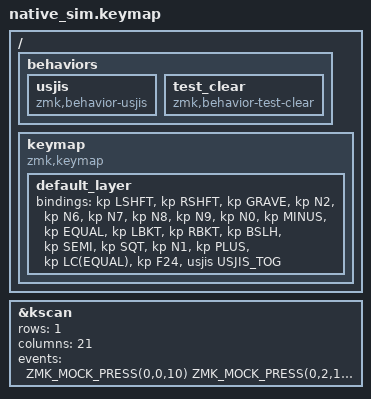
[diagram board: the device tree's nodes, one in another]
/* Generated by tests/zmk/generate.py; do not edit. */
#include <dt-bindings/zmk/keys.h>
#include <behaviors.dtsi>
#include <dt-bindings/zmk/kscan_mock.h>
#include <dt-bindings/zmk/usjis.h>

&kscan {
    rows = <1>;
    columns = <21>;
    events = <
        ZMK_MOCK_PRESS(0,0,10)
        ZMK_MOCK_PRESS(0,2,10)
        ZMK_MOCK_RELEASE(0,2,10)
        ZMK_MOCK_RELEASE(0,0,10)
        ZMK_MOCK_PRESS(0,0,10)
        ZMK_MOCK_PRESS(0,2,10)
        ZMK_MOCK_RELEASE(0,0,10)
        ZMK_MOCK_RELEASE(0,2,10)
        ZMK_MOCK_PRESS(0,1,10)
        ZMK_MOCK_PRESS(0,2,10)
        ZMK_MOCK_RELEASE(0,2,10)
        ZMK_MOCK_RELEASE(0,1,10)
        ZMK_MOCK_PRESS(0,1,10)
        ZMK_MOCK_PRESS(0,2,10)
        ZMK_MOCK_RELEASE(0,1,10)
        ZMK_MOCK_RELEASE(0,2,10)
        ZMK_MOCK_PRESS(0,0,10)
        ZMK_MOCK_PRESS(0,1,10)
        ZMK_MOCK_PRESS(0,2,10)
        ZMK_MOCK_RELEASE(0,2,10)
        ZMK_MOCK_RELEASE(0,1,10)
        ZMK_MOCK_RELEASE(0,0,10)
        ZMK_MOCK_PRESS(0,0,10)
        ZMK_MOCK_PRESS(0,1,10)
        ZMK_MOCK_PRESS(0,2,10)
        ZMK_MOCK_RELEASE(0,1,10)
        ZMK_MOCK_RELEASE(0,0,10)
        ZMK_MOCK_RELEASE(0,2,10)
        ZMK_MOCK_PRESS(0,19,10)
        ZMK_MOCK_RELEASE(0,19,10)
        ZMK_MOCK_PRESS(0,0,10)
        ZMK_MOCK_PRESS(0,3,10)
        ZMK_MOCK_RELEASE(0,3,10)
        ZMK_MOCK_RELEASE(0,0,10)
        ZMK_MOCK_PRESS(0,0,10)
        ZMK_MOCK_PRESS(0,3,10)
        ZMK_MOCK_RELEASE(0,0,10)
        ZMK_MOCK_RELEASE(0,3,10)
        ZMK_MOCK_PRESS(0,1,10)
        ZMK_MOCK_PRESS(0,3,10)
        ZMK_MOCK_RELEASE(0,3,10)
        ZMK_MOCK_RELEASE(0,1,10)
        ZMK_MOCK_PRESS(0,1,10)
        ZMK_MOCK_PRESS(0,3,10)
        ZMK_MOCK_RELEASE(0,1,10)
        ZMK_MOCK_RELEASE(0,3,10)
        ZMK_MOCK_PRESS(0,0,10)
        ZMK_MOCK_PRESS(0,1,10)
        ZMK_MOCK_PRESS(0,3,10)
        ZMK_MOCK_RELEASE(0,3,10)
        ZMK_MOCK_RELEASE(0,1,10)
        ZMK_MOCK_RELEASE(0,0,10)
        ZMK_MOCK_PRESS(0,0,10)
        ZMK_MOCK_PRESS(0,1,10)
        ZMK_MOCK_PRESS(0,3,10)
        ZMK_MOCK_RELEASE(0,1,10)
        ZMK_MOCK_RELEASE(0,0,10)
        ZMK_MOCK_RELEASE(0,3,10)
        ZMK_MOCK_PRESS(0,19,10)
        ZMK_MOCK_RELEASE(0,19,10)
        ZMK_MOCK_PRESS(0,0,10)
        ZMK_MOCK_PRESS(0,4,10)
        ZMK_MOCK_RELEASE(0,4,10)
        ZMK_MOCK_RELEASE(0,0,10)
        ZMK_MOCK_PRESS(0,0,10)
        ZMK_MOCK_PRESS(0,4,10)
        ZMK_MOCK_RELEASE(0,0,10)
        ZMK_MOCK_RELEASE(0,4,10)
        ZMK_MOCK_PRESS(0,1,10)
        ZMK_MOCK_PRESS(0,4,10)
        ZMK_MOCK_RELEASE(0,4,10)
        ZMK_MOCK_RELEASE(0,1,10)
        ZMK_MOCK_PRESS(0,1,10)
        ZMK_MOCK_PRESS(0,4,10)
        ZMK_MOCK_RELEASE(0,1,10)
        ZMK_MOCK_RELEASE(0,4,10)
        ZMK_MOCK_PRESS(0,0,10)
        ZMK_MOCK_PRESS(0,1,10)
        ZMK_MOCK_PRESS(0,4,10)
        ZMK_MOCK_RELEASE(0,4,10)
        ZMK_MOCK_RELEASE(0,1,10)
        ZMK_MOCK_RELEASE(0,0,10)
        ZMK_MOCK_PRESS(0,0,10)
        ZMK_MOCK_PRESS(0,1,10)
        ZMK_MOCK_PRESS(0,4,10)
        ZMK_MOCK_RELEASE(0,1,10)
        ZMK_MOCK_RELEASE(0,0,10)
        ZMK_MOCK_RELEASE(0,4,10)
        ZMK_MOCK_PRESS(0,19,10)
        ZMK_MOCK_RELEASE(0,19,10)
        ZMK_MOCK_PRESS(0,0,10)
        ZMK_MOCK_PRESS(0,5,10)
        ZMK_MOCK_RELEASE(0,5,10)
        ZMK_MOCK_RELEASE(0,0,10)
        ZMK_MOCK_PRESS(0,0,10)
        ZMK_MOCK_PRESS(0,5,10)
        ZMK_MOCK_RELEASE(0,0,10)
        ZMK_MOCK_RELEASE(0,5,10)
        ZMK_MOCK_PRESS(0,1,10)
        ZMK_MOCK_PRESS(0,5,10)
        ZMK_MOCK_RELEASE(0,5,10)
        ZMK_MOCK_RELEASE(0,1,10)
        ZMK_MOCK_PRESS(0,1,10)
        ZMK_MOCK_PRESS(0,5,10)
        ZMK_MOCK_RELEASE(0,1,10)
        ZMK_MOCK_RELEASE(0,5,10)
        ZMK_MOCK_PRESS(0,0,10)
        ZMK_MOCK_PRESS(0,1,10)
        ZMK_MOCK_PRESS(0,5,10)
        ZMK_MOCK_RELEASE(0,5,10)
        ZMK_MOCK_RELEASE(0,1,10)
        ZMK_MOCK_RELEASE(0,0,10)
        ZMK_MOCK_PRESS(0,0,10)
        ZMK_MOCK_PRESS(0,1,10)
        ZMK_MOCK_PRESS(0,5,10)
        ZMK_MOCK_RELEASE(0,1,10)
        ZMK_MOCK_RELEASE(0,0,10)
        ZMK_MOCK_RELEASE(0,5,10)
        ZMK_MOCK_PRESS(0,19,10)
        ZMK_MOCK_RELEASE(0,19,10)
        ZMK_MOCK_PRESS(0,0,10)
        ZMK_MOCK_PRESS(0,6,10)
        ZMK_MOCK_RELEASE(0,6,10)
        ZMK_MOCK_RELEASE(0,0,10)
        ZMK_MOCK_PRESS(0,0,10)
        ZMK_MOCK_PRESS(0,6,10)
        ZMK_MOCK_RELEASE(0,0,10)
        ZMK_MOCK_RELEASE(0,6,10)
        ZMK_MOCK_PRESS(0,1,10)
        ZMK_MOCK_PRESS(0,6,10)
        ZMK_MOCK_RELEASE(0,6,10)
        ZMK_MOCK_RELEASE(0,1,10)
        ZMK_MOCK_PRESS(0,1,10)
        ZMK_MOCK_PRESS(0,6,10)
        ZMK_MOCK_RELEASE(0,1,10)
        ZMK_MOCK_RELEASE(0,6,10)
        ZMK_MOCK_PRESS(0,0,10)
        ZMK_MOCK_PRESS(0,1,10)
        ZMK_MOCK_PRESS(0,6,10)
        ZMK_MOCK_RELEASE(0,6,10)
        ZMK_MOCK_RELEASE(0,1,10)
        ZMK_MOCK_RELEASE(0,0,10)
        ZMK_MOCK_PRESS(0,0,10)
        ZMK_MOCK_PRESS(0,1,10)
        ZMK_MOCK_PRESS(0,6,10)
        ZMK_MOCK_RELEASE(0,1,10)
        ZMK_MOCK_RELEASE(0,0,10)
        ZMK_MOCK_RELEASE(0,6,10)
        ZMK_MOCK_PRESS(0,19,10)
        ZMK_MOCK_RELEASE(0,19,10)
        ZMK_MOCK_PRESS(0,0,10)
        ZMK_MOCK_PRESS(0,7,10)
        ZMK_MOCK_RELEASE(0,7,10)
        ZMK_MOCK_RELEASE(0,0,10)
        ZMK_MOCK_PRESS(0,0,10)
        ZMK_MOCK_PRESS(0,7,10)
        ZMK_MOCK_RELEASE(0,0,10)
        ZMK_MOCK_RELEASE(0,7,10)
        ZMK_MOCK_PRESS(0,1,10)
        ZMK_MOCK_PRESS(0,7,10)
        ZMK_MOCK_RELEASE(0,7,10)
        ZMK_MOCK_RELEASE(0,1,10)
        ZMK_MOCK_PRESS(0,1,10)
        ZMK_MOCK_PRESS(0,7,10)
        ZMK_MOCK_RELEASE(0,1,10)
        ZMK_MOCK_RELEASE(0,7,10)
        ZMK_MOCK_PRESS(0,0,10)
        ZMK_MOCK_PRESS(0,1,10)
        ZMK_MOCK_PRESS(0,7,10)
        ZMK_MOCK_RELEASE(0,7,10)
        ZMK_MOCK_RELEASE(0,1,10)
        ZMK_MOCK_RELEASE(0,0,10)
        ZMK_MOCK_PRESS(0,0,10)
        ZMK_MOCK_PRESS(0,1,10)
        ZMK_MOCK_PRESS(0,7,10)
        ZMK_MOCK_RELEASE(0,1,10)
        ZMK_MOCK_RELEASE(0,0,10)
        ZMK_MOCK_RELEASE(0,7,10)
        ZMK_MOCK_PRESS(0,19,10)
        ZMK_MOCK_RELEASE(0,19,10)
        ZMK_MOCK_PRESS(0,0,10)
        ZMK_MOCK_PRESS(0,8,10)
        ZMK_MOCK_RELEASE(0,8,10)
        ZMK_MOCK_RELEASE(0,0,10)
        ZMK_MOCK_PRESS(0,0,10)
        ZMK_MOCK_PRESS(0,8,10)
        ZMK_MOCK_RELEASE(0,0,10)
        ZMK_MOCK_RELEASE(0,8,10)
        ZMK_MOCK_PRESS(0,1,10)
        ZMK_MOCK_PRESS(0,8,10)
        ZMK_MOCK_RELEASE(0,8,10)
        ZMK_MOCK_RELEASE(0,1,10)
        ZMK_MOCK_PRESS(0,1,10)
        ZMK_MOCK_PRESS(0,8,10)
        ZMK_MOCK_RELEASE(0,1,10)
        ZMK_MOCK_RELEASE(0,8,10)
        ZMK_MOCK_PRESS(0,0,10)
        ZMK_MOCK_PRESS(0,1,10)
        ZMK_MOCK_PRESS(0,8,10)
        ZMK_MOCK_RELEASE(0,8,10)
        ZMK_MOCK_RELEASE(0,1,10)
        ZMK_MOCK_RELEASE(0,0,10)
        ZMK_MOCK_PRESS(0,0,10)
        ZMK_MOCK_PRESS(0,1,10)
        ZMK_MOCK_PRESS(0,8,10)
        ZMK_MOCK_RELEASE(0,1,10)
        ZMK_MOCK_RELEASE(0,0,10)
        ZMK_MOCK_RELEASE(0,8,10)
        ZMK_MOCK_PRESS(0,19,10)
        ZMK_MOCK_RELEASE(0,19,10)
        ZMK_MOCK_PRESS(0,0,10)
        ZMK_MOCK_PRESS(0,9,10)
        ZMK_MOCK_RELEASE(0,9,10)
        ZMK_MOCK_RELEASE(0,0,10)
        ZMK_MOCK_PRESS(0,0,10)
        ZMK_MOCK_PRESS(0,9,10)
        ZMK_MOCK_RELEASE(0,0,10)
        ZMK_MOCK_RELEASE(0,9,10)
        ZMK_MOCK_PRESS(0,1,10)
        ZMK_MOCK_PRESS(0,9,10)
        ZMK_MOCK_RELEASE(0,9,10)
        ZMK_MOCK_RELEASE(0,1,10)
        ZMK_MOCK_PRESS(0,1,10)
        ZMK_MOCK_PRESS(0,9,10)
        ZMK_MOCK_RELEASE(0,1,10)
        ZMK_MOCK_RELEASE(0,9,10)
        ZMK_MOCK_PRESS(0,0,10)
        ZMK_MOCK_PRESS(0,1,10)
        ZMK_MOCK_PRESS(0,9,10)
        ZMK_MOCK_RELEASE(0,9,10)
        ZMK_MOCK_RELEASE(0,1,10)
        ZMK_MOCK_RELEASE(0,0,10)
        ZMK_MOCK_PRESS(0,0,10)
        ZMK_MOCK_PRESS(0,1,10)
        ZMK_MOCK_PRESS(0,9,10)
        ZMK_MOCK_RELEASE(0,1,10)
        ZMK_MOCK_RELEASE(0,0,10)
        ZMK_MOCK_RELEASE(0,9,10)
        ZMK_MOCK_PRESS(0,19,10)
        ZMK_MOCK_RELEASE(0,19,10)
        ZMK_MOCK_PRESS(0,10,10)
        ZMK_MOCK_RELEASE(0,10,10)
        ZMK_MOCK_PRESS(0,19,10)
        ZMK_MOCK_RELEASE(0,19,10)
        ZMK_MOCK_PRESS(0,0,10)
        ZMK_MOCK_PRESS(0,10,10)
        ZMK_MOCK_RELEASE(0,10,10)
        ZMK_MOCK_RELEASE(0,0,10)
        ZMK_MOCK_PRESS(0,0,10)
        ZMK_MOCK_PRESS(0,10,10)
        ZMK_MOCK_RELEASE(0,0,10)
        ZMK_MOCK_RELEASE(0,10,10)
        ZMK_MOCK_PRESS(0,1,10)
        ZMK_MOCK_PRESS(0,10,10)
        ZMK_MOCK_RELEASE(0,10,10)
        ZMK_MOCK_RELEASE(0,1,10)
        ZMK_MOCK_PRESS(0,1,10)
        ZMK_MOCK_PRESS(0,10,10)
        ZMK_MOCK_RELEASE(0,1,10)
        ZMK_MOCK_RELEASE(0,10,10)
        ZMK_MOCK_PRESS(0,0,10)
        ZMK_MOCK_PRESS(0,1,10)
        ZMK_MOCK_PRESS(0,10,10)
        ZMK_MOCK_RELEASE(0,10,10)
        ZMK_MOCK_RELEASE(0,1,10)
        ZMK_MOCK_RELEASE(0,0,10)
        ZMK_MOCK_PRESS(0,0,10)
        ZMK_MOCK_PRESS(0,1,10)
        ZMK_MOCK_PRESS(0,10,10)
        ZMK_MOCK_RELEASE(0,1,10)
        ZMK_MOCK_RELEASE(0,0,10)
        ZMK_MOCK_RELEASE(0,10,10)
        ZMK_MOCK_PRESS(0,19,10)
        ZMK_MOCK_RELEASE(0,19,10)
        ZMK_MOCK_PRESS(0,11,10)
        ZMK_MOCK_RELEASE(0,11,10)
        ZMK_MOCK_PRESS(0,19,10)
        ZMK_MOCK_RELEASE(0,19,10)
        ZMK_MOCK_PRESS(0,0,10)
        ZMK_MOCK_PRESS(0,11,10)
        ZMK_MOCK_RELEASE(0,11,10)
        ZMK_MOCK_RELEASE(0,0,10)
        ZMK_MOCK_PRESS(0,0,10)
        ZMK_MOCK_PRESS(0,11,10)
        ZMK_MOCK_RELEASE(0,0,10)
        ZMK_MOCK_RELEASE(0,11,10)
        ZMK_MOCK_PRESS(0,1,10)
        ZMK_MOCK_PRESS(0,11,10)
        ZMK_MOCK_RELEASE(0,11,10)
        ZMK_MOCK_RELEASE(0,1,10)
        ZMK_MOCK_PRESS(0,1,10)
        ZMK_MOCK_PRESS(0,11,10)
        ZMK_MOCK_RELEASE(0,1,10)
        ZMK_MOCK_RELEASE(0,11,10)
        ZMK_MOCK_PRESS(0,0,10)
        ZMK_MOCK_PRESS(0,1,10)
        ZMK_MOCK_PRESS(0,11,10)
        ZMK_MOCK_RELEASE(0,11,10)
        ZMK_MOCK_RELEASE(0,1,10)
        ZMK_MOCK_RELEASE(0,0,10)
        ZMK_MOCK_PRESS(0,0,10)
        ZMK_MOCK_PRESS(0,1,10)
        ZMK_MOCK_PRESS(0,11,10)
        ZMK_MOCK_RELEASE(0,1,10)
        ZMK_MOCK_RELEASE(0,0,10)
        ZMK_MOCK_RELEASE(0,11,10)
        ZMK_MOCK_PRESS(0,19,10)
        ZMK_MOCK_RELEASE(0,19,10)
        ZMK_MOCK_PRESS(0,12,10)
        ZMK_MOCK_RELEASE(0,12,10)
        ZMK_MOCK_PRESS(0,19,10)
        ZMK_MOCK_RELEASE(0,19,10)
        ZMK_MOCK_PRESS(0,0,10)
        ZMK_MOCK_PRESS(0,12,10)
        ZMK_MOCK_RELEASE(0,12,10)
        ZMK_MOCK_RELEASE(0,0,10)
        ZMK_MOCK_PRESS(0,0,10)
        ZMK_MOCK_PRESS(0,12,10)
        ZMK_MOCK_RELEASE(0,0,10)
        ZMK_MOCK_RELEASE(0,12,10)
        ZMK_MOCK_PRESS(0,1,10)
        ZMK_MOCK_PRESS(0,12,10)
        ZMK_MOCK_RELEASE(0,12,10)
        ZMK_MOCK_RELEASE(0,1,10)
        ZMK_MOCK_PRESS(0,1,10)
        ZMK_MOCK_PRESS(0,12,10)
        ZMK_MOCK_RELEASE(0,1,10)
        ZMK_MOCK_RELEASE(0,12,10)
        ZMK_MOCK_PRESS(0,0,10)
        ZMK_MOCK_PRESS(0,1,10)
        ZMK_MOCK_PRESS(0,12,10)
        ZMK_MOCK_RELEASE(0,12,10)
        ZMK_MOCK_RELEASE(0,1,10)
        ZMK_MOCK_RELEASE(0,0,10)
        ZMK_MOCK_PRESS(0,0,10)
        ZMK_MOCK_PRESS(0,1,10)
        ZMK_MOCK_PRESS(0,12,10)
        ZMK_MOCK_RELEASE(0,1,10)
        ZMK_MOCK_RELEASE(0,0,10)
        ZMK_MOCK_RELEASE(0,12,10)
        ZMK_MOCK_PRESS(0,19,10)
        ZMK_MOCK_RELEASE(0,19,10)
        ZMK_MOCK_PRESS(0,13,10)
        ZMK_MOCK_RELEASE(0,13,10)
        ZMK_MOCK_PRESS(0,19,10)
        ZMK_MOCK_RELEASE(0,19,10)
        ZMK_MOCK_PRESS(0,0,10)
        ZMK_MOCK_PRESS(0,13,10)
        ZMK_MOCK_RELEASE(0,13,10)
        ZMK_MOCK_RELEASE(0,0,10)
        ZMK_MOCK_PRESS(0,0,10)
        ZMK_MOCK_PRESS(0,13,10)
        ZMK_MOCK_RELEASE(0,0,10)
        ZMK_MOCK_RELEASE(0,13,10)
        ZMK_MOCK_PRESS(0,1,10)
        ZMK_MOCK_PRESS(0,13,10)
        ZMK_MOCK_RELEASE(0,13,10)
        ZMK_MOCK_RELEASE(0,1,10)
        ZMK_MOCK_PRESS(0,1,10)
        ZMK_MOCK_PRESS(0,13,10)
        ZMK_MOCK_RELEASE(0,1,10)
        ZMK_MOCK_RELEASE(0,13,10)
        ZMK_MOCK_PRESS(0,0,10)
        ZMK_MOCK_PRESS(0,1,10)
        ZMK_MOCK_PRESS(0,13,10)
        ZMK_MOCK_RELEASE(0,13,10)
        ZMK_MOCK_RELEASE(0,1,10)
        ZMK_MOCK_RELEASE(0,0,10)
        ZMK_MOCK_PRESS(0,0,10)
        ZMK_MOCK_PRESS(0,1,10)
        ZMK_MOCK_PRESS(0,13,10)
        ZMK_MOCK_RELEASE(0,1,10)
        ZMK_MOCK_RELEASE(0,0,10)
        ZMK_MOCK_RELEASE(0,13,10)
        ZMK_MOCK_PRESS(0,19,10)
        ZMK_MOCK_RELEASE(0,19,10)
        ZMK_MOCK_PRESS(0,0,10)
        ZMK_MOCK_PRESS(0,14,10)
        ZMK_MOCK_RELEASE(0,14,10)
        ZMK_MOCK_RELEASE(0,0,10)
        ZMK_MOCK_PRESS(0,0,10)
        ZMK_MOCK_PRESS(0,14,10)
        ZMK_MOCK_RELEASE(0,0,10)
        ZMK_MOCK_RELEASE(0,14,10)
        ZMK_MOCK_PRESS(0,1,10)
        ZMK_MOCK_PRESS(0,14,10)
        ZMK_MOCK_RELEASE(0,14,10)
        ZMK_MOCK_RELEASE(0,1,10)
        ZMK_MOCK_PRESS(0,1,10)
        ZMK_MOCK_PRESS(0,14,10)
        ZMK_MOCK_RELEASE(0,1,10)
        ZMK_MOCK_RELEASE(0,14,10)
        ZMK_MOCK_PRESS(0,0,10)
        ZMK_MOCK_PRESS(0,1,10)
        ZMK_MOCK_PRESS(0,14,10)
        ZMK_MOCK_RELEASE(0,14,10)
        ZMK_MOCK_RELEASE(0,1,10)
        ZMK_MOCK_RELEASE(0,0,10)
        ZMK_MOCK_PRESS(0,0,10)
        ZMK_MOCK_PRESS(0,1,10)
        ZMK_MOCK_PRESS(0,14,10)
        ZMK_MOCK_RELEASE(0,1,10)
        ZMK_MOCK_RELEASE(0,0,10)
        ZMK_MOCK_RELEASE(0,14,10)
        ZMK_MOCK_PRESS(0,19,10)
        ZMK_MOCK_RELEASE(0,19,10)
        ZMK_MOCK_PRESS(0,15,10)
        ZMK_MOCK_RELEASE(0,15,10)
        ZMK_MOCK_PRESS(0,19,10)
        ZMK_MOCK_RELEASE(0,19,10)
        ZMK_MOCK_PRESS(0,0,10)
        ZMK_MOCK_PRESS(0,15,10)
        ZMK_MOCK_RELEASE(0,15,10)
        ZMK_MOCK_RELEASE(0,0,10)
        ZMK_MOCK_PRESS(0,0,10)
        ZMK_MOCK_PRESS(0,15,10)
        ZMK_MOCK_RELEASE(0,0,10)
        ZMK_MOCK_RELEASE(0,15,10)
        ZMK_MOCK_PRESS(0,1,10)
        ZMK_MOCK_PRESS(0,15,10)
        ZMK_MOCK_RELEASE(0,15,10)
        ZMK_MOCK_RELEASE(0,1,10)
        ZMK_MOCK_PRESS(0,1,10)
        ZMK_MOCK_PRESS(0,15,10)
        ZMK_MOCK_RELEASE(0,1,10)
        ZMK_MOCK_RELEASE(0,15,10)
        ZMK_MOCK_PRESS(0,0,10)
        ZMK_MOCK_PRESS(0,1,10)
        ZMK_MOCK_PRESS(0,15,10)
        ZMK_MOCK_RELEASE(0,15,10)
        ZMK_MOCK_RELEASE(0,1,10)
        ZMK_MOCK_RELEASE(0,0,10)
        ZMK_MOCK_PRESS(0,0,10)
        ZMK_MOCK_PRESS(0,1,10)
        ZMK_MOCK_PRESS(0,15,10)
        ZMK_MOCK_RELEASE(0,1,10)
        ZMK_MOCK_RELEASE(0,0,10)
        ZMK_MOCK_RELEASE(0,15,10)
        ZMK_MOCK_PRESS(0,19,10)
        ZMK_MOCK_RELEASE(0,19,10)
        ZMK_MOCK_PRESS(0,2,10)
        ZMK_MOCK_RELEASE(0,2,10)
        ZMK_MOCK_PRESS(0,19,10)
        ZMK_MOCK_RELEASE(0,19,10)
        ZMK_MOCK_PRESS(0,3,10)
        ZMK_MOCK_RELEASE(0,3,10)
        ZMK_MOCK_PRESS(0,4,10)
        ZMK_MOCK_RELEASE(0,4,10)
        ZMK_MOCK_PRESS(0,5,10)
        ZMK_MOCK_RELEASE(0,5,10)
        ZMK_MOCK_PRESS(0,6,10)
        ZMK_MOCK_RELEASE(0,6,10)
        ZMK_MOCK_PRESS(0,7,10)
        ZMK_MOCK_RELEASE(0,7,10)
        ZMK_MOCK_PRESS(0,8,10)
        ZMK_MOCK_RELEASE(0,8,10)
        ZMK_MOCK_PRESS(0,9,10)
        ZMK_MOCK_RELEASE(0,9,10)
        ZMK_MOCK_PRESS(0,14,10)
        ZMK_MOCK_RELEASE(0,14,10)
        ZMK_MOCK_PRESS(0,1,10)
        ZMK_MOCK_PRESS(0,16,10)
        ZMK_MOCK_RELEASE(0,16,10)
        ZMK_MOCK_RELEASE(0,1,10)
        ZMK_MOCK_PRESS(0,19,10)
        ZMK_MOCK_RELEASE(0,19,10)
        ZMK_MOCK_PRESS(0,17,10)
        ZMK_MOCK_RELEASE(0,17,10)
        ZMK_MOCK_PRESS(0,18,10)
        ZMK_MOCK_RELEASE(0,18,10)
        ZMK_MOCK_PRESS(0,19,10)
        ZMK_MOCK_RELEASE(0,19,10)
        ZMK_MOCK_PRESS(0,20,10)
        ZMK_MOCK_RELEASE(0,20,10)
        ZMK_MOCK_PRESS(0,0,10)
        ZMK_MOCK_PRESS(0,2,10)
        ZMK_MOCK_RELEASE(0,2,10)
        ZMK_MOCK_RELEASE(0,0,10)
        ZMK_MOCK_PRESS(0,0,10)
        ZMK_MOCK_PRESS(0,2,10)
        ZMK_MOCK_RELEASE(0,0,10)
        ZMK_MOCK_RELEASE(0,2,10)
        ZMK_MOCK_PRESS(0,1,10)
        ZMK_MOCK_PRESS(0,2,10)
        ZMK_MOCK_RELEASE(0,2,10)
        ZMK_MOCK_RELEASE(0,1,10)
        ZMK_MOCK_PRESS(0,1,10)
        ZMK_MOCK_PRESS(0,2,10)
        ZMK_MOCK_RELEASE(0,1,10)
        ZMK_MOCK_RELEASE(0,2,10)
        ZMK_MOCK_PRESS(0,0,10)
        ZMK_MOCK_PRESS(0,1,10)
        ZMK_MOCK_PRESS(0,2,10)
        ZMK_MOCK_RELEASE(0,2,10)
        ZMK_MOCK_RELEASE(0,1,10)
        ZMK_MOCK_RELEASE(0,0,10)
        ZMK_MOCK_PRESS(0,0,10)
        ZMK_MOCK_PRESS(0,1,10)
        ZMK_MOCK_PRESS(0,2,10)
        ZMK_MOCK_RELEASE(0,1,10)
        ZMK_MOCK_RELEASE(0,0,10)
        ZMK_MOCK_RELEASE(0,2,10)
        ZMK_MOCK_PRESS(0,19,10)
        ZMK_MOCK_RELEASE(0,19,10)
        ZMK_MOCK_PRESS(0,0,10)
        ZMK_MOCK_PRESS(0,3,10)
        ZMK_MOCK_RELEASE(0,3,10)
        ZMK_MOCK_RELEASE(0,0,10)
        ZMK_MOCK_PRESS(0,0,10)
        ZMK_MOCK_PRESS(0,3,10)
        ZMK_MOCK_RELEASE(0,0,10)
        ZMK_MOCK_RELEASE(0,3,10)
        ZMK_MOCK_PRESS(0,1,10)
        ZMK_MOCK_PRESS(0,3,10)
        ZMK_MOCK_RELEASE(0,3,10)
        ZMK_MOCK_RELEASE(0,1,10)
        ZMK_MOCK_PRESS(0,1,10)
        ZMK_MOCK_PRESS(0,3,10)
        ZMK_MOCK_RELEASE(0,1,10)
        ZMK_MOCK_RELEASE(0,3,10)
        ZMK_MOCK_PRESS(0,0,10)
        ZMK_MOCK_PRESS(0,1,10)
        ZMK_MOCK_PRESS(0,3,10)
        ZMK_MOCK_RELEASE(0,3,10)
        ZMK_MOCK_RELEASE(0,1,10)
        ZMK_MOCK_RELEASE(0,0,10)
        ZMK_MOCK_PRESS(0,0,10)
        ZMK_MOCK_PRESS(0,1,10)
        ZMK_MOCK_PRESS(0,3,10)
        ZMK_MOCK_RELEASE(0,1,10)
        ZMK_MOCK_RELEASE(0,0,10)
        ZMK_MOCK_RELEASE(0,3,10)
        ZMK_MOCK_PRESS(0,19,10)
        ZMK_MOCK_RELEASE(0,19,10)
        ZMK_MOCK_PRESS(0,0,10)
        ZMK_MOCK_PRESS(0,4,10)
        ZMK_MOCK_RELEASE(0,4,10)
        ZMK_MOCK_RELEASE(0,0,10)
        ZMK_MOCK_PRESS(0,0,10)
        ZMK_MOCK_PRESS(0,4,10)
        ZMK_MOCK_RELEASE(0,0,10)
        ZMK_MOCK_RELEASE(0,4,10)
        ZMK_MOCK_PRESS(0,1,10)
        ZMK_MOCK_PRESS(0,4,10)
        ZMK_MOCK_RELEASE(0,4,10)
        ZMK_MOCK_RELEASE(0,1,10)
        ZMK_MOCK_PRESS(0,1,10)
        ZMK_MOCK_PRESS(0,4,10)
        ZMK_MOCK_RELEASE(0,1,10)
        ZMK_MOCK_RELEASE(0,4,10)
        ZMK_MOCK_PRESS(0,0,10)
        ZMK_MOCK_PRESS(0,1,10)
        ZMK_MOCK_PRESS(0,4,10)
        ZMK_MOCK_RELEASE(0,4,10)
        ZMK_MOCK_RELEASE(0,1,10)
        ZMK_MOCK_RELEASE(0,0,10)
        ZMK_MOCK_PRESS(0,0,10)
        ZMK_MOCK_PRESS(0,1,10)
        ZMK_MOCK_PRESS(0,4,10)
        ZMK_MOCK_RELEASE(0,1,10)
        ZMK_MOCK_RELEASE(0,0,10)
        ZMK_MOCK_RELEASE(0,4,10)
        ZMK_MOCK_PRESS(0,19,10)
        ZMK_MOCK_RELEASE(0,19,10)
        ZMK_MOCK_PRESS(0,0,10)
        ZMK_MOCK_PRESS(0,5,10)
        ZMK_MOCK_RELEASE(0,5,10)
        ZMK_MOCK_RELEASE(0,0,10)
        ZMK_MOCK_PRESS(0,0,10)
        ZMK_MOCK_PRESS(0,5,10)
        ZMK_MOCK_RELEASE(0,0,10)
        ZMK_MOCK_RELEASE(0,5,10)
        ZMK_MOCK_PRESS(0,1,10)
        ZMK_MOCK_PRESS(0,5,10)
        ZMK_MOCK_RELEASE(0,5,10)
        ZMK_MOCK_RELEASE(0,1,10)
        ZMK_MOCK_PRESS(0,1,10)
        ZMK_MOCK_PRESS(0,5,10)
        ZMK_MOCK_RELEASE(0,1,10)
        ZMK_MOCK_RELEASE(0,5,10)
        ZMK_MOCK_PRESS(0,0,10)
        ZMK_MOCK_PRESS(0,1,10)
        ZMK_MOCK_PRESS(0,5,10)
        ZMK_MOCK_RELEASE(0,5,10)
        ZMK_MOCK_RELEASE(0,1,10)
        ZMK_MOCK_RELEASE(0,0,10)
        ZMK_MOCK_PRESS(0,0,10)
        ZMK_MOCK_PRESS(0,1,10)
        ZMK_MOCK_PRESS(0,5,10)
        ZMK_MOCK_RELEASE(0,1,10)
        ZMK_MOCK_RELEASE(0,0,10)
        ZMK_MOCK_RELEASE(0,5,10)
        ZMK_MOCK_PRESS(0,19,10)
        ZMK_MOCK_RELEASE(0,19,10)
        ZMK_MOCK_PRESS(0,0,10)
        ZMK_MOCK_PRESS(0,6,10)
        ZMK_MOCK_RELEASE(0,6,10)
        ZMK_MOCK_RELEASE(0,0,10)
        ZMK_MOCK_PRESS(0,0,10)
        ZMK_MOCK_PRESS(0,6,10)
        ZMK_MOCK_RELEASE(0,0,10)
        ZMK_MOCK_RELEASE(0,6,10)
        ZMK_MOCK_PRESS(0,1,10)
        ZMK_MOCK_PRESS(0,6,10)
        ZMK_MOCK_RELEASE(0,6,10)
        ZMK_MOCK_RELEASE(0,1,10)
        ZMK_MOCK_PRESS(0,1,10)
        ZMK_MOCK_PRESS(0,6,10)
        ZMK_MOCK_RELEASE(0,1,10)
        ZMK_MOCK_RELEASE(0,6,10)
        ZMK_MOCK_PRESS(0,0,10)
        ZMK_MOCK_PRESS(0,1,10)
        ZMK_MOCK_PRESS(0,6,10)
        ZMK_MOCK_RELEASE(0,6,10)
        ZMK_MOCK_RELEASE(0,1,10)
        ZMK_MOCK_RELEASE(0,0,10)
        ZMK_MOCK_PRESS(0,0,10)
        ZMK_MOCK_PRESS(0,1,10)
        ZMK_MOCK_PRESS(0,6,10)
        ZMK_MOCK_RELEASE(0,1,10)
        ZMK_MOCK_RELEASE(0,0,10)
        ZMK_MOCK_RELEASE(0,6,10)
        ZMK_MOCK_PRESS(0,19,10)
        ZMK_MOCK_RELEASE(0,19,10)
        ZMK_MOCK_PRESS(0,0,10)
        ZMK_MOCK_PRESS(0,7,10)
        ZMK_MOCK_RELEASE(0,7,10)
        ZMK_MOCK_RELEASE(0,0,10)
        ZMK_MOCK_PRESS(0,0,10)
        ZMK_MOCK_PRESS(0,7,10)
        ZMK_MOCK_RELEASE(0,0,10)
        ZMK_MOCK_RELEASE(0,7,10)
        ZMK_MOCK_PRESS(0,1,10)
        ZMK_MOCK_PRESS(0,7,10)
        ZMK_MOCK_RELEASE(0,7,10)
        ZMK_MOCK_RELEASE(0,1,10)
        ZMK_MOCK_PRESS(0,1,10)
        ZMK_MOCK_PRESS(0,7,10)
        ZMK_MOCK_RELEASE(0,1,10)
        ZMK_MOCK_RELEASE(0,7,10)
        ZMK_MOCK_PRESS(0,0,10)
        ZMK_MOCK_PRESS(0,1,10)
        ZMK_MOCK_PRESS(0,7,10)
        ZMK_MOCK_RELEASE(0,7,10)
        ZMK_MOCK_RELEASE(0,1,10)
        ZMK_MOCK_RELEASE(0,0,10)
        ZMK_MOCK_PRESS(0,0,10)
        ZMK_MOCK_PRESS(0,1,10)
        ZMK_MOCK_PRESS(0,7,10)
        ZMK_MOCK_RELEASE(0,1,10)
        ZMK_MOCK_RELEASE(0,0,10)
        ZMK_MOCK_RELEASE(0,7,10)
        ZMK_MOCK_PRESS(0,19,10)
        ZMK_MOCK_RELEASE(0,19,10)
        ZMK_MOCK_PRESS(0,0,10)
        ZMK_MOCK_PRESS(0,8,10)
        ZMK_MOCK_RELEASE(0,8,10)
        ZMK_MOCK_RELEASE(0,0,10)
        ZMK_MOCK_PRESS(0,0,10)
        ZMK_MOCK_PRESS(0,8,10)
        ZMK_MOCK_RELEASE(0,0,10)
        ZMK_MOCK_RELEASE(0,8,10)
        ZMK_MOCK_PRESS(0,1,10)
        ZMK_MOCK_PRESS(0,8,10)
        ZMK_MOCK_RELEASE(0,8,10)
        ZMK_MOCK_RELEASE(0,1,10)
        ZMK_MOCK_PRESS(0,1,10)
        ZMK_MOCK_PRESS(0,8,10)
        ZMK_MOCK_RELEASE(0,1,10)
        ZMK_MOCK_RELEASE(0,8,10)
        ZMK_MOCK_PRESS(0,0,10)
        ZMK_MOCK_PRESS(0,1,10)
        ZMK_MOCK_PRESS(0,8,10)
        ZMK_MOCK_RELEASE(0,8,10)
        ZMK_MOCK_RELEASE(0,1,10)
        ZMK_MOCK_RELEASE(0,0,10)
        ZMK_MOCK_PRESS(0,0,10)
        ZMK_MOCK_PRESS(0,1,10)
        ZMK_MOCK_PRESS(0,8,10)
        ZMK_MOCK_RELEASE(0,1,10)
        ZMK_MOCK_RELEASE(0,0,10)
        ZMK_MOCK_RELEASE(0,8,10)
        ZMK_MOCK_PRESS(0,19,10)
        ZMK_MOCK_RELEASE(0,19,10)
        ZMK_MOCK_PRESS(0,0,10)
        ZMK_MOCK_PRESS(0,9,10)
        ZMK_MOCK_RELEASE(0,9,10)
        ZMK_MOCK_RELEASE(0,0,10)
        ZMK_MOCK_PRESS(0,0,10)
        ZMK_MOCK_PRESS(0,9,10)
        ZMK_MOCK_RELEASE(0,0,10)
        ZMK_MOCK_RELEASE(0,9,10)
        ZMK_MOCK_PRESS(0,1,10)
        ZMK_MOCK_PRESS(0,9,10)
        ZMK_MOCK_RELEASE(0,9,10)
        ZMK_MOCK_RELEASE(0,1,10)
        ZMK_MOCK_PRESS(0,1,10)
        ZMK_MOCK_PRESS(0,9,10)
        ZMK_MOCK_RELEASE(0,1,10)
        ZMK_MOCK_RELEASE(0,9,10)
        ZMK_MOCK_PRESS(0,0,10)
        ZMK_MOCK_PRESS(0,1,10)
        ZMK_MOCK_PRESS(0,9,10)
        ZMK_MOCK_RELEASE(0,9,10)
        ZMK_MOCK_RELEASE(0,1,10)
        ZMK_MOCK_RELEASE(0,0,10)
        ZMK_MOCK_PRESS(0,0,10)
        ZMK_MOCK_PRESS(0,1,10)
        ZMK_MOCK_PRESS(0,9,10)
        ZMK_MOCK_RELEASE(0,1,10)
        ZMK_MOCK_RELEASE(0,0,10)
        ZMK_MOCK_RELEASE(0,9,10)
        ZMK_MOCK_PRESS(0,19,10)
        ZMK_MOCK_RELEASE(0,19,10)
        ZMK_MOCK_PRESS(0,10,10)
        ZMK_MOCK_RELEASE(0,10,10)
        ZMK_MOCK_PRESS(0,19,10)
        ZMK_MOCK_RELEASE(0,19,10)
        ZMK_MOCK_PRESS(0,0,10)
        ZMK_MOCK_PRESS(0,10,10)
        ZMK_MOCK_RELEASE(0,10,10)
        ZMK_MOCK_RELEASE(0,0,10)
        ZMK_MOCK_PRESS(0,0,10)
        ZMK_MOCK_PRESS(0,10,10)
        ZMK_MOCK_RELEASE(0,0,10)
        ZMK_MOCK_RELEASE(0,10,10)
        ZMK_MOCK_PRESS(0,1,10)
        ZMK_MOCK_PRESS(0,10,10)
        ZMK_MOCK_RELEASE(0,10,10)
        ZMK_MOCK_RELEASE(0,1,10)
        ZMK_MOCK_PRESS(0,1,10)
        ZMK_MOCK_PRESS(0,10,10)
        ZMK_MOCK_RELEASE(0,1,10)
        ZMK_MOCK_RELEASE(0,10,10)
        ZMK_MOCK_PRESS(0,0,10)
        ZMK_MOCK_PRESS(0,1,10)
        ZMK_MOCK_PRESS(0,10,10)
        ZMK_MOCK_RELEASE(0,10,10)
        ZMK_MOCK_RELEASE(0,1,10)
        ZMK_MOCK_RELEASE(0,0,10)
        ZMK_MOCK_PRESS(0,0,10)
        ZMK_MOCK_PRESS(0,1,10)
        ZMK_MOCK_PRESS(0,10,10)
        ZMK_MOCK_RELEASE(0,1,10)
        ZMK_MOCK_RELEASE(0,0,10)
        ZMK_MOCK_RELEASE(0,10,10)
        ZMK_MOCK_PRESS(0,19,10)
        ZMK_MOCK_RELEASE(0,19,10)
        ZMK_MOCK_PRESS(0,11,10)
        ZMK_MOCK_RELEASE(0,11,10)
        ZMK_MOCK_PRESS(0,19,10)
        ZMK_MOCK_RELEASE(0,19,10)
        ZMK_MOCK_PRESS(0,0,10)
        ZMK_MOCK_PRESS(0,11,10)
        ZMK_MOCK_RELEASE(0,11,10)
        ZMK_MOCK_RELEASE(0,0,10)
        ZMK_MOCK_PRESS(0,0,10)
        ZMK_MOCK_PRESS(0,11,10)
        ZMK_MOCK_RELEASE(0,0,10)
        ZMK_MOCK_RELEASE(0,11,10)
        ZMK_MOCK_PRESS(0,1,10)
        ZMK_MOCK_PRESS(0,11,10)
        ZMK_MOCK_RELEASE(0,11,10)
        ZMK_MOCK_RELEASE(0,1,10)
        ZMK_MOCK_PRESS(0,1,10)
        ZMK_MOCK_PRESS(0,11,10)
        ZMK_MOCK_RELEASE(0,1,10)
        ZMK_MOCK_RELEASE(0,11,10)
        ZMK_MOCK_PRESS(0,0,10)
        ZMK_MOCK_PRESS(0,1,10)
        ZMK_MOCK_PRESS(0,11,10)
        ZMK_MOCK_RELEASE(0,11,10)
        ZMK_MOCK_RELEASE(0,1,10)
        ZMK_MOCK_RELEASE(0,0,10)
        ZMK_MOCK_PRESS(0,0,10)
        ZMK_MOCK_PRESS(0,1,10)
        ZMK_MOCK_PRESS(0,11,10)
        ZMK_MOCK_RELEASE(0,1,10)
        ZMK_MOCK_RELEASE(0,0,10)
        ZMK_MOCK_RELEASE(0,11,10)
        ZMK_MOCK_PRESS(0,19,10)
        ZMK_MOCK_RELEASE(0,19,10)
        ZMK_MOCK_PRESS(0,12,10)
        ZMK_MOCK_RELEASE(0,12,10)
        ZMK_MOCK_PRESS(0,19,10)
        ZMK_MOCK_RELEASE(0,19,10)
        ZMK_MOCK_PRESS(0,0,10)
        ZMK_MOCK_PRESS(0,12,10)
        ZMK_MOCK_RELEASE(0,12,10)
        ZMK_MOCK_RELEASE(0,0,10)
        ZMK_MOCK_PRESS(0,0,10)
        ZMK_MOCK_PRESS(0,12,10)
        ZMK_MOCK_RELEASE(0,0,10)
        ZMK_MOCK_RELEASE(0,12,10)
        ZMK_MOCK_PRESS(0,1,10)
        ZMK_MOCK_PRESS(0,12,10)
        ZMK_MOCK_RELEASE(0,12,10)
        ZMK_MOCK_RELEASE(0,1,10)
        ZMK_MOCK_PRESS(0,1,10)
        ZMK_MOCK_PRESS(0,12,10)
        ZMK_MOCK_RELEASE(0,1,10)
        ZMK_MOCK_RELEASE(0,12,10)
        ZMK_MOCK_PRESS(0,0,10)
        ZMK_MOCK_PRESS(0,1,10)
        ZMK_MOCK_PRESS(0,12,10)
        ZMK_MOCK_RELEASE(0,12,10)
        ZMK_MOCK_RELEASE(0,1,10)
        ZMK_MOCK_RELEASE(0,0,10)
        ZMK_MOCK_PRESS(0,0,10)
        ZMK_MOCK_PRESS(0,1,10)
        ZMK_MOCK_PRESS(0,12,10)
        ZMK_MOCK_RELEASE(0,1,10)
        ZMK_MOCK_RELEASE(0,0,10)
        ZMK_MOCK_RELEASE(0,12,10)
        ZMK_MOCK_PRESS(0,19,10)
        ZMK_MOCK_RELEASE(0,19,10)
        ZMK_MOCK_PRESS(0,13,10)
        ZMK_MOCK_RELEASE(0,13,10)
        ZMK_MOCK_PRESS(0,19,10)
        ZMK_MOCK_RELEASE(0,19,10)
        ZMK_MOCK_PRESS(0,0,10)
        ZMK_MOCK_PRESS(0,13,10)
        ZMK_MOCK_RELEASE(0,13,10)
        ZMK_MOCK_RELEASE(0,0,10)
        ZMK_MOCK_PRESS(0,0,10)
        ZMK_MOCK_PRESS(0,13,10)
        ZMK_MOCK_RELEASE(0,0,10)
        ZMK_MOCK_RELEASE(0,13,10)
        ZMK_MOCK_PRESS(0,1,10)
        ZMK_MOCK_PRESS(0,13,10)
        ZMK_MOCK_RELEASE(0,13,10)
        ZMK_MOCK_RELEASE(0,1,10)
        ZMK_MOCK_PRESS(0,1,10)
        ZMK_MOCK_PRESS(0,13,10)
        ZMK_MOCK_RELEASE(0,1,10)
        ZMK_MOCK_RELEASE(0,13,10)
        ZMK_MOCK_PRESS(0,0,10)
        ZMK_MOCK_PRESS(0,1,10)
        ZMK_MOCK_PRESS(0,13,10)
        ZMK_MOCK_RELEASE(0,13,10)
        ZMK_MOCK_RELEASE(0,1,10)
        ZMK_MOCK_RELEASE(0,0,10)
        ZMK_MOCK_PRESS(0,0,10)
        ZMK_MOCK_PRESS(0,1,10)
        ZMK_MOCK_PRESS(0,13,10)
        ZMK_MOCK_RELEASE(0,1,10)
        ZMK_MOCK_RELEASE(0,0,10)
        ZMK_MOCK_RELEASE(0,13,10)
        ZMK_MOCK_PRESS(0,19,10)
        ZMK_MOCK_RELEASE(0,19,10)
        ZMK_MOCK_PRESS(0,0,10)
        ZMK_MOCK_PRESS(0,14,10)
        ZMK_MOCK_RELEASE(0,14,10)
        ZMK_MOCK_RELEASE(0,0,10)
        ZMK_MOCK_PRESS(0,0,10)
        ZMK_MOCK_PRESS(0,14,10)
        ZMK_MOCK_RELEASE(0,0,10)
        ZMK_MOCK_RELEASE(0,14,10)
        ZMK_MOCK_PRESS(0,1,10)
        ZMK_MOCK_PRESS(0,14,10)
        ZMK_MOCK_RELEASE(0,14,10)
        ZMK_MOCK_RELEASE(0,1,10)
        ZMK_MOCK_PRESS(0,1,10)
        ZMK_MOCK_PRESS(0,14,10)
        ZMK_MOCK_RELEASE(0,1,10)
        ZMK_MOCK_RELEASE(0,14,10)
        ZMK_MOCK_PRESS(0,0,10)
        ZMK_MOCK_PRESS(0,1,10)
        ZMK_MOCK_PRESS(0,14,10)
        ZMK_MOCK_RELEASE(0,14,10)
        ZMK_MOCK_RELEASE(0,1,10)
        ZMK_MOCK_RELEASE(0,0,10)
        ZMK_MOCK_PRESS(0,0,10)
        ZMK_MOCK_PRESS(0,1,10)
        ZMK_MOCK_PRESS(0,14,10)
        ZMK_MOCK_RELEASE(0,1,10)
        ZMK_MOCK_RELEASE(0,0,10)
        ZMK_MOCK_RELEASE(0,14,10)
        ZMK_MOCK_PRESS(0,19,10)
        ZMK_MOCK_RELEASE(0,19,10)
        ZMK_MOCK_PRESS(0,15,10)
        ZMK_MOCK_RELEASE(0,15,10)
        ZMK_MOCK_PRESS(0,19,10)
        ZMK_MOCK_RELEASE(0,19,10)
        ZMK_MOCK_PRESS(0,0,10)
        ZMK_MOCK_PRESS(0,15,10)
        ZMK_MOCK_RELEASE(0,15,10)
        ZMK_MOCK_RELEASE(0,0,10)
        ZMK_MOCK_PRESS(0,0,10)
        ZMK_MOCK_PRESS(0,15,10)
        ZMK_MOCK_RELEASE(0,0,10)
        ZMK_MOCK_RELEASE(0,15,10)
        ZMK_MOCK_PRESS(0,1,10)
        ZMK_MOCK_PRESS(0,15,10)
        ZMK_MOCK_RELEASE(0,15,10)
        ZMK_MOCK_RELEASE(0,1,10)
        ZMK_MOCK_PRESS(0,1,10)
        ZMK_MOCK_PRESS(0,15,10)
        ZMK_MOCK_RELEASE(0,1,10)
        ZMK_MOCK_RELEASE(0,15,10)
        ZMK_MOCK_PRESS(0,0,10)
        ZMK_MOCK_PRESS(0,1,10)
        ZMK_MOCK_PRESS(0,15,10)
        ZMK_MOCK_RELEASE(0,15,10)
        ZMK_MOCK_RELEASE(0,1,10)
        ZMK_MOCK_RELEASE(0,0,10)
        ZMK_MOCK_PRESS(0,0,10)
        ZMK_MOCK_PRESS(0,1,10)
        ZMK_MOCK_PRESS(0,15,10)
        ZMK_MOCK_RELEASE(0,1,10)
        ZMK_MOCK_RELEASE(0,0,10)
        ZMK_MOCK_RELEASE(0,15,10)
        ZMK_MOCK_PRESS(0,19,10)
        ZMK_MOCK_RELEASE(0,19,10)
        ZMK_MOCK_PRESS(0,2,10)
        ZMK_MOCK_RELEASE(0,2,10)
        ZMK_MOCK_PRESS(0,19,10)
        ZMK_MOCK_RELEASE(0,19,10)
        ZMK_MOCK_PRESS(0,17,10)
        ZMK_MOCK_RELEASE(0,17,10)
        ZMK_MOCK_PRESS(0,18,10)
        ZMK_MOCK_RELEASE(0,18,10)
    >;
};

/ {
    behaviors {
        usjis: usjis {
            compatible = "zmk,behavior-usjis";
            #binding-cells = <1>;
        };
        test_clear: test_clear {
            compatible = "zmk,behavior-test-clear";
            #binding-cells = <0>;
        };
    };
};

/ {
    keymap {
        compatible = "zmk,keymap";
        default_layer {
            bindings = <
                &kp LSHFT
                &kp RSHFT
                &kp GRAVE
                &kp N2
                &kp N6
                &kp N7
                &kp N8
                &kp N9
                &kp N0
                &kp MINUS
                &kp EQUAL
                &kp LBKT
                &kp RBKT
                &kp BSLH
                &kp SEMI
                &kp SQT
                &kp N1
                &kp PLUS
                &kp LC(EQUAL)
                &kp F24
                &usjis USJIS_TOG
            >;
        };
    };
};
